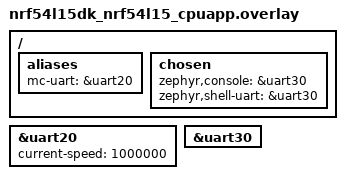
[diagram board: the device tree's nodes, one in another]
/*
 * SPDX-FileCopyrightText: Copyright The Zephyr Project Contributors
 * SPDX-License-Identifier: Apache-2.0
 */

/ {
	aliases {
		mc-uart = &uart20;
	};

	chosen {
		zephyr,console = &uart30;
		zephyr,shell-uart = &uart30;
	};
};

&uart20 {
	current-speed = <1000000>;
};

&uart30 {
	status = "okay";
};
